# AE512F80F5582LS_CM55_HE_View register map
Vendor: Alif Semiconductor; Series: E5; File version: 1.0
CPU: CM55 r1p0, selectable endian, MPU, FPU, double-precision FPU, DSP, VTOR, 8 interrupt priority bits, 1 SAU regions
Registers are 32-bit, read-write, reset 0x0 unless marked. A register's access mark holds for its fields unless they carry their own. Offsets are from the block's base; [hi:lo] are bit positions; lines under a group give offsets from that group; {n}, {i} and the like mark numbered series.

## VBAT
Base 0x1A609000
0x00 GPIO_CTRL — GPIO 1.8 V / 3.3 V Power Control Register
  [0] VOLT — Select voltage level for the 1.8-V/3.3-V (flex) I/O pins
    0=I/O pin will be used with a 3.3-V power; 1=I/O pin will be used with a 1.8-V power
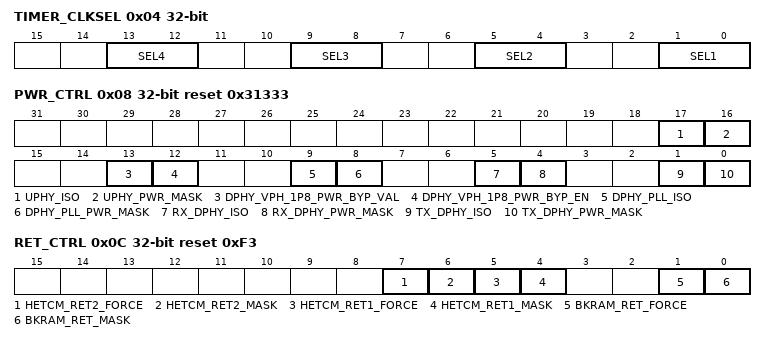
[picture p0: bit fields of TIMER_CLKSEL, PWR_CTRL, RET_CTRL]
0x04 TIMER_CLKSEL — LPTIMER Clock Select Register
  [13:12] SEL4 — LPTIMER3 clock select
    0=S32K_CLK; 1=128K_CLK (128 kHz); 2=External clock from LPTMR3_CLK_IO pin; 3=LPTIMER2 toggle output (LPTMR2_OUT)
  [9:8] SEL3 — LPTIMER2 clock select
    0=S32K_CLK; 1=128K_CLK (128 kHz); 2=External clock from LPTMR2_CLK_IO pin; 3=S32K_CLK
  [5:4] SEL2 — LPTIMER1 clock select
    0=S32K_CLK; 1=128K_CLK (128 kHz); 2=External clock from LPTMR1_CLK_IO pin; 3=LPTIMER0 toggle output (LPTMR0_OUT)
  [1:0] SEL1 — LPTIMER0 clock select
    0=S32K_CLK; 1=128K_CLK (128 kHz); 2=External clock from LPTMR0_CLK_IO pin; 3=S32K_CLK
0x08 PWR_CTRL reset 0x31333 — Power Control Register
  [17] UPHY_ISO — Enable isolation for USB PHY
    0=Disable; 1=Enable
  [16] UPHY_PWR_MASK — Mask off the power for USB PHY
    0=Power not masked; 1=Power masked off
  [13] DPHY_VPH_1P8_PWR_BYP_VAL — Power setting for MIPI D-PHY 1.8 V supply. The setting is used only if DPHY_VPH_1P8_PWR_BYP_EN bit is enabled.
    0=Power disabled; 1=Power enabled
  [12] DPHY_VPH_1P8_PWR_BYP_EN — Power mode for MIPI D-PHY 1.8 V supply
    0=Power enabled whenever PD-6 is enabled; 1=Power specified by DPHY_VPH_1P8_PWR_BYP_VAL bit
  [9] DPHY_PLL_ISO — Enable isolation for MIPI PLL
    0=Disable; 1=Enable
  [8] DPHY_PLL_PWR_MASK — Mask off the power for MIPI PLL
    0=Power not masked; 1=Power masked off
  [5] RX_DPHY_ISO — Enable isolation for MIPI RX DPHY
    0=Disable; 1=Enable
  [4] RX_DPHY_PWR_MASK — Mask off the power for MIPI RX DPHY
    0=Power not masked; 1=Power masked off
  [1] TX_DPHY_ISO — Enable isolation for MIPI TX DPHY
    0=Disable; 1=Enable
  [0] TX_DPHY_PWR_MASK — Mask off the power for MIPI TX DPHY
    0=Power not masked; 1=Power masked off
0x0C RET_CTRL reset 0xF3 — Memory Retention Control Register
  [7] HETCM_RET2_FORCE — Memory retention force for M55-HE TCM RET2
    0=Force enabling the memory retention; 1=No force
  [6] HETCM_RET2_MASK — Memory retention mask for M55-HE TCM RET2
    0=No mask; 1=Disable the memory retention
  [5] HETCM_RET1_FORCE — Memory retention force for M55-HE TCM RET1
    0=Force enabling the memory retention; 1=No force
  [4] HETCM_RET1_MASK — Memory retention mask for M55-HE TCM RET1
    0=No mask; 1=Disable the memory retention
  [1] BKRAM_RET_FORCE — Memory retention force for Utility SRAM
    0=Force enabling the memory retention; 1=No force
  [0] BKRAM_RET_MASK — Memory retention mask for Utility SRAM
    0=No mask; 1=Disable the memory retention
0x10 RTC_CLK_EN — LPRTC Clock Enable Register
  [0] CLK_EN — Enable SYST_PCLK and S32K_CLK for LPRTC. This bit must be set before any programming to LPRTC.
    0=Disable LPRTC clocks; 1=Enable LPRTC clocks

## STOP_MODE
Base 0x1A60F000
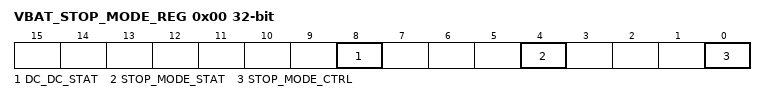
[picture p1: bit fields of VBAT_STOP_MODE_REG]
0x00 VBAT_STOP_MODE_REG — VBAT Stop Mode Control and Status Register
  [8] DC_DC_STAT ro — DC-DC Status Reflects the real-time status of DC-DC power
    0=DC-DC is ON; 1=DC-DC is OFF
  [4] STOP_MODE_STAT write-1-clears — Stop Mode Status - HW sets this bit when DC-DC was turned off - SW clears this bit by writing 0x1
  [0] STOP_MODE_CTRL — Stop Mode Control - SW sets this bit to enter stop mode - HW clears this bit when there is a wake-up event

## EVTRTR2
Base 0x400E2000
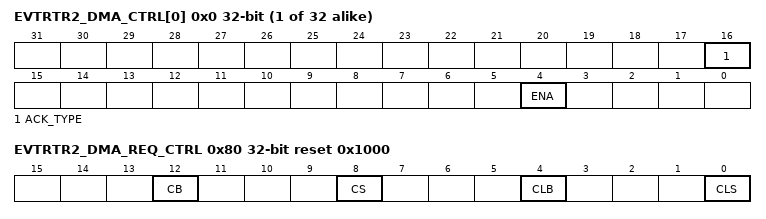
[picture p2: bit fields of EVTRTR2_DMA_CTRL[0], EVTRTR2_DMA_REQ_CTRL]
{0x0+4i} EVTRTR2_DMA_CTRL[{i}] (i=0..31) — DMA/Event Router Control and Status Register (n)
  [16] ACK_TYPE ro — DMA handshake type status for DMA peripheral
    0=Peripheral completes the REQ-ACK handshake with DMA controller. Event Router passing through REQ-ACK between DMA controller and peripheral.; 1=Event Router completes the REQ-ACK handshake with DMA controller. Peripheral raises DMA request without responding to ACK from DMA controller.
  [4] ENA — DMA channel enable
    0=Disable DMA channel; 1=Enable DMA channel
0x80 EVTRTR2_DMA_REQ_CTRL reset 0x1000 — DMA Request Control Register
  [all] fields
    0=Disable; 1=Enable
  [12] CB — Enable DMA request on DMACBREQ (DMAC Burst Request) Note: It is recommended to enable all DMA requests on the burst request line (DMACBREQ). For single transfer, the number of beats in a burst should be set to 1 (DMA_CCRn[SRC_BURST_LEN] = 0x0).
  [8] CS — Enable DMA request on DMACSREQ (DMAC Single Request) Note: It is recommended to enable all DMA requests on the burst request line (DMACBREQ), even for single transfer.
  [4] CLB — Enable DMA request on DMACLBREQ (DMAC Last Burst Request) Note: Do not use. The current implementation does not support transfers from a peripheral with an unspecified length ('peripheral length management').
  [0] CLS — Enable DMA request on DMACLSREQ (DMAC Last Single Request) Note: Do not use. The current implementation does not support transfers from a peripheral with an unspecified length ('peripheral length management').
0x90 EVTRTR2_DMA_ACK_TYPE0 reset not defined — DMA Handshake Type Register 0
  [31:0] ACK — Select DMA handshake type for DMA group #0
